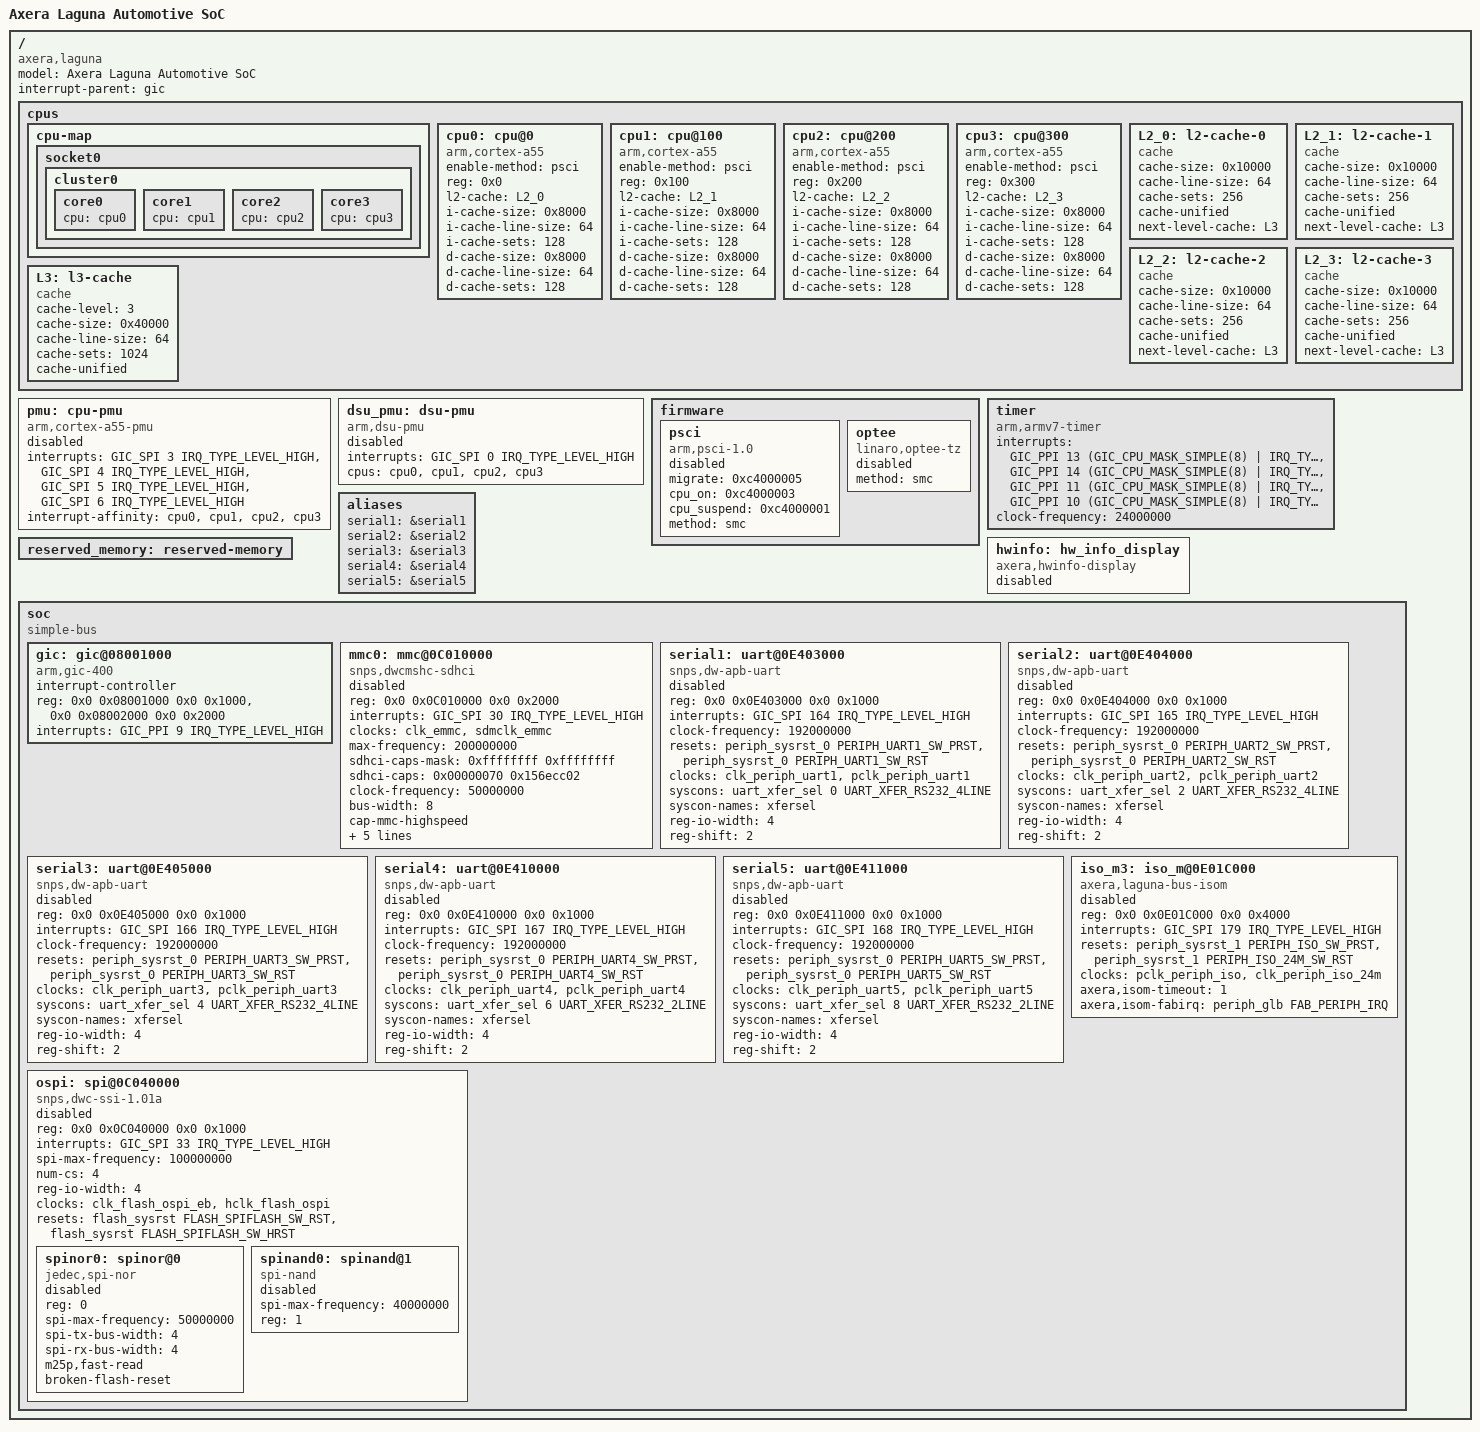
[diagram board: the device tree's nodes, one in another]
/* SPDX-License-Identifier: GPL-2.0+
 *
 * Axera Laguna SoC device tree
 *
 * Copyright (C) 2024 Charleye <wangkart@aliyun.com>
 */

/ {
	model = "Axera Laguna Automotive SoC";
	compatible = "axera,laguna";
	#address-cells = <2>;
	#size-cells = <2>;
	interrupt-parent = <&gic>;

	cpus {
		#size-cells = <0>;
		#address-cells = <1>;

		cpu-map {
			socket0 {
				cluster0 {
					core0 {
						cpu = <&cpu0>;
					};
					core1 {
						cpu = <&cpu1>;
					};
					core2 {
						cpu = <&cpu2>;
					};
					core3 {
						cpu = <&cpu3>;
					};
				};
			};
		};

		cpu0: cpu@0 {
			compatible = "arm,cortex-a55";
			device_type = "cpu";
			enable-method = "psci";
			reg = <0x0>;

			l2-cache = <&L2_0>;
			i-cache-size = <0x8000>;
			i-cache-line-size = <64>;
			i-cache-sets = <128>;
			d-cache-size = <0x8000>;
			d-cache-line-size = <64>;
			d-cache-sets = <128>;
		};

		cpu1: cpu@100 {
			compatible = "arm,cortex-a55";
			device_type = "cpu";
			enable-method = "psci";
			reg = <0x100>;

			l2-cache = <&L2_1>;
			i-cache-size = <0x8000>;
			i-cache-line-size = <64>;
			i-cache-sets = <128>;
			d-cache-size = <0x8000>;
			d-cache-line-size = <64>;
			d-cache-sets = <128>;
		};

		cpu2: cpu@200 {
			compatible = "arm,cortex-a55";
			device_type = "cpu";
			enable-method = "psci";
			reg = <0x200>;

			l2-cache = <&L2_2>;
			i-cache-size = <0x8000>;
			i-cache-line-size = <64>;
			i-cache-sets = <128>;
			d-cache-size = <0x8000>;
			d-cache-line-size = <64>;
			d-cache-sets = <128>;
		};
		cpu3: cpu@300 {
			compatible = "arm,cortex-a55";
			device_type = "cpu";
			enable-method = "psci";
			reg = <0x300>;

			l2-cache = <&L2_3>;
			i-cache-size = <0x8000>;
			i-cache-line-size = <64>;
			i-cache-sets = <128>;
			d-cache-size = <0x8000>;
			d-cache-line-size = <64>;
			d-cache-sets = <128>;
		};

		L2_0: l2-cache-0 {
			compatible = "cache";
			cache-size = <0x10000>;
			cache-line-size = <64>;
			cache-sets = <256>;
			cache-unified;
			next-level-cache = <&L3>;
		};

		L2_1: l2-cache-1 {
			compatible = "cache";
			cache-size = <0x10000>;
			cache-line-size = <64>;
			cache-sets = <256>;
			cache-unified;
			next-level-cache = <&L3>;
		};

		L2_2: l2-cache-2 {
			compatible = "cache";
			cache-size = <0x10000>;
			cache-line-size = <64>;
			cache-sets = <256>;
			cache-unified;
			next-level-cache = <&L3>;
		};

		L2_3: l2-cache-3 {
			compatible = "cache";
			cache-size = <0x10000>;
			cache-line-size = <64>;
			cache-sets = <256>;
			cache-unified;
			next-level-cache = <&L3>;
		};

		L3: l3-cache {
			compatible = "cache";
			cache-level = <3>;
			cache-size = <0x40000>;
			cache-line-size = <64>;
			cache-sets = <1024>;
			cache-unified;
		};
	};

	pmu: cpu-pmu {
		compatible = "arm,cortex-a55-pmu";
		interrupts = <GIC_SPI 3 IRQ_TYPE_LEVEL_HIGH>,
		             <GIC_SPI 4 IRQ_TYPE_LEVEL_HIGH>,
		             <GIC_SPI 5 IRQ_TYPE_LEVEL_HIGH>,
		             <GIC_SPI 6 IRQ_TYPE_LEVEL_HIGH>;
		interrupt-affinity = <&cpu0>, <&cpu1>, <&cpu2>, <&cpu3>;
		status = "disabled";
	};

	dsu_pmu: dsu-pmu {
		compatible = "arm,dsu-pmu";
		interrupts = <GIC_SPI 0 IRQ_TYPE_LEVEL_HIGH>;
		cpus = <&cpu0>, <&cpu1>, <&cpu2>, <&cpu3>;
		status = "disabled";
	};

	firmware {
		psci: psci {
			compatible = "arm,psci-1.0", "arm,psci-0.2";
			migrate = <0xc4000005>;
			cpu_on = <0xc4000003>;
			cpu_suspend = <0xc4000001>;
			method = "smc";
			status = "disabled";
		};

		optee: optee {
			compatible = "linaro,optee-tz";
			method = "smc";
			status = "disabled";
		};
	};

	timer {
		compatible = "arm,armv7-timer";
		interrupts = <GIC_PPI 13 (GIC_CPU_MASK_SIMPLE(8) | IRQ_TYPE_LEVEL_HIGH)>,
		             <GIC_PPI 14 (GIC_CPU_MASK_SIMPLE(8) | IRQ_TYPE_LEVEL_HIGH)>,
		             <GIC_PPI 11 (GIC_CPU_MASK_SIMPLE(8) | IRQ_TYPE_LEVEL_HIGH)>,
		             <GIC_PPI 10 (GIC_CPU_MASK_SIMPLE(8) | IRQ_TYPE_LEVEL_HIGH)>;
		clock-frequency = <24000000>;
	};

	aliases {
		serial1 = &serial1;
		serial2 = &serial2;
		serial3 = &serial3;
		serial4 = &serial4;
		serial5 = &serial5;
	};

	reserved_memory: reserved-memory {
		#address-cells = <2>;
		#size-cells = <2>;
		ranges;

		/* filled by u-boot */
	};

	hwinfo: hw_info_display {
		compatible = "axera,hwinfo-display";
		status = "disabled";

		/* filled by u-boot */
	};

	soc {
		compatible = "simple-bus";
		#address-cells = <2>;
		#size-cells = <2>;
		ranges;

		gic: gic@08001000 {
			compatible = "arm,gic-400";
			interrupt-controller;
			reg = <0x0 0x08001000 0x0 0x1000>,
			      <0x0 0x08002000 0x0 0x2000>;
			interrupts = <GIC_PPI 9 IRQ_TYPE_LEVEL_HIGH>;
			#interrupt-cells = <3>;
		};

		mmc0: mmc@0C010000 {
			compatible = "snps,dwcmshc-sdhci";
			reg = <0x0 0x0C010000 0x0 0x2000>;
			interrupts = <GIC_SPI 30 IRQ_TYPE_LEVEL_HIGH>;
			clocks = <&clk_emmc>, <&sdmclk_emmc>;
			clock-names = "core", "bus";
			max-frequency = <200000000>;
			sdhci-caps-mask = <0xffffffff 0xffffffff>;
			sdhci-caps = <0x00000070 0x156ecc02>;
			clock-frequency = <50000000>;
			bus-width = <8>;
			cap-mmc-highspeed;
			mmc-ddr-1_8v;
			mmc-hs200-1_8v;
			non-removable;
			no-sdio;
			no-sd;
			status = "disabled";
		};

		serial1: uart@0E403000 {
			compatible = "snps,dw-apb-uart";
			reg = <0x0 0x0E403000 0x0 0x1000>;
			interrupts = <GIC_SPI 164 IRQ_TYPE_LEVEL_HIGH>;
			clock-frequency = <192000000>; //192MHz
			resets = <&periph_sysrst_0 PERIPH_UART1_SW_PRST>,
			         <&periph_sysrst_0 PERIPH_UART1_SW_RST>;
			reset-names = "apb_prst", "baudrst";
			clocks = <&clk_periph_uart1>, <&pclk_periph_uart1>;
			clock-names = "baudclk", "apb_pclk";
			syscons = <&uart_xfer_sel 0 UART_XFER_RS232_4LINE>;
			syscon-names = "xfersel";
			reg-io-width = <4>;
			reg-shift = <2>;
			status = "disabled";
		};

		serial2: uart@0E404000 {
			compatible = "snps,dw-apb-uart";
			reg = <0x0 0x0E404000 0x0 0x1000>;
			interrupts = <GIC_SPI 165 IRQ_TYPE_LEVEL_HIGH>;
			clock-frequency = <192000000>; //192MHz
			resets = <&periph_sysrst_0 PERIPH_UART2_SW_PRST>,
			         <&periph_sysrst_0 PERIPH_UART2_SW_RST>;
			reset-names = "apb_prst", "baudrst";
			clocks = <&clk_periph_uart2>, <&pclk_periph_uart2>;
			clock-names = "baudclk", "apb_pclk";
			syscons = <&uart_xfer_sel 2 UART_XFER_RS232_4LINE>;
			syscon-names = "xfersel";
			reg-io-width = <4>;
			reg-shift = <2>;
			status = "disabled";
		};

		serial3: uart@0E405000 {
			compatible = "snps,dw-apb-uart";
			reg = <0x0 0x0E405000 0x0 0x1000>;
			interrupts = <GIC_SPI 166 IRQ_TYPE_LEVEL_HIGH>;
			clock-frequency = <192000000>; //192MHz
			resets = <&periph_sysrst_0 PERIPH_UART3_SW_PRST>,
			         <&periph_sysrst_0 PERIPH_UART3_SW_RST>;
			reset-names = "apb_prst", "baudrst";
			clocks = <&clk_periph_uart3>, <&pclk_periph_uart3>;
			clock-names = "baudclk", "apb_pclk";
			syscons = <&uart_xfer_sel 4 UART_XFER_RS232_4LINE>;
			syscon-names = "xfersel";
			reg-io-width = <4>;
			reg-shift = <2>;
			status = "disabled";
		};

		serial4: uart@0E410000 {
			compatible = "snps,dw-apb-uart";
			reg = <0x0 0x0E410000 0x0 0x1000>;
			interrupts = <GIC_SPI 167 IRQ_TYPE_LEVEL_HIGH>;
			clock-frequency = <192000000>; //192MHz
			resets = <&periph_sysrst_0 PERIPH_UART4_SW_PRST>,
			         <&periph_sysrst_0 PERIPH_UART4_SW_RST>;
			reset-names = "apb_prst", "baudrst";
			clocks = <&clk_periph_uart4>, <&pclk_periph_uart4>;
			clock-names = "baudclk", "apb_pclk";
			syscons = <&uart_xfer_sel 6 UART_XFER_RS232_2LINE>;
			syscon-names = "xfersel";
			reg-io-width = <4>;
			reg-shift = <2>;
			status = "disabled";
		};

		serial5: uart@0E411000 {
			compatible = "snps,dw-apb-uart";
			reg = <0x0 0x0E411000 0x0 0x1000>;
			interrupts = <GIC_SPI 168 IRQ_TYPE_LEVEL_HIGH>;
			clock-frequency = <192000000>; //192MHz
			resets = <&periph_sysrst_0 PERIPH_UART5_SW_PRST>,
			         <&periph_sysrst_0 PERIPH_UART5_SW_RST>;
			reset-names = "apb_prst", "baudrst";
			clocks = <&clk_periph_uart5>, <&pclk_periph_uart5>;
			clock-names = "baudclk", "apb_pclk";
			syscons = <&uart_xfer_sel 8 UART_XFER_RS232_2LINE>;
			syscon-names = "xfersel";
			reg-io-width = <4>;
			reg-shift = <2>;
			status = "disabled";
		};

		iso_m3: iso_m@0E01C000 {
			compatible = "axera,laguna-bus-isom";
			reg = <0x0 0x0E01C000 0x0 0x4000>;
			interrupts = <GIC_SPI 179 IRQ_TYPE_LEVEL_HIGH>;
			interrupt-names = "periph_sys_fab";
			resets = <&periph_sysrst_1 PERIPH_ISO_SW_PRST>,
			         <&periph_sysrst_1 PERIPH_ISO_24M_SW_RST>;
			reset-names = "apb_prst", "isom_rst";
			clocks = <&pclk_periph_iso>, <&clk_periph_iso_24m>;
			clock-names = "apb_pclk", "isom_clk";
			axera,isom-timeout = <1>;
			// axera,isom-bypass;
			axera,isom-fabirq = <&periph_glb FAB_PERIPH_IRQ>;
			status = "disabled";
		};

		ospi: spi@0C040000 {
			#address-cells = <1>;
			#size-cells = <0>;
			compatible ="snps,dwc-ssi-1.01a";
			reg = <0x0 0x0C040000 0x0 0x1000>;
			interrupts = <GIC_SPI 33 IRQ_TYPE_LEVEL_HIGH>;
			spi-max-frequency = <100000000>;
			num-cs = <4>;
			reg-io-width = <4>;
			clocks = <&clk_flash_ospi_eb>,
			         <&hclk_flash_ospi>;
			clock-names = "ssi_clk", "pclk";
			resets = <&flash_sysrst FLASH_SPIFLASH_SW_RST>,
			         <&flash_sysrst FLASH_SPIFLASH_SW_HRST>;
			reset-names = "spi", "apb_prst";
			status = "disabled";

			spinor0: spinor@0 {
				#address-cells = <1>;
				#size-cells = <1>;
				compatible = "jedec,spi-nor";
				reg = <0>;
				spi-max-frequency = <50000000>;
				spi-tx-bus-width = <4>;
				spi-rx-bus-width = <4>;
				m25p,fast-read;
				broken-flash-reset;
				status = "disabled";
			};

			spinand0: spinand@1 {
				#address-cells = <1>;
				#size-cells = <1>;
				compatible = "spi-nand";
				spi-max-frequency = <40000000>;
				reg = <1>;
				status = "disabled";
			};
		};
	};
};
